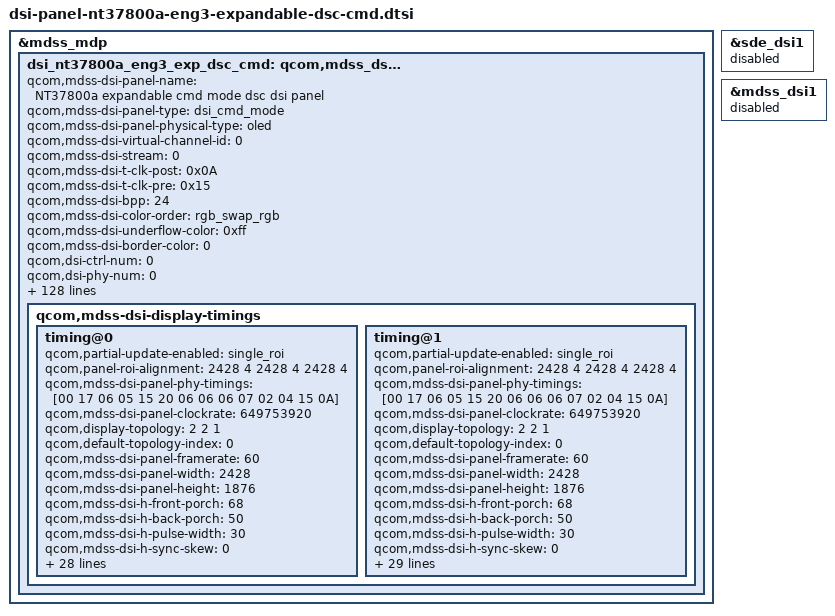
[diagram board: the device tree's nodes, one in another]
/* Copyright (c) 2014, Code Aurora Forum. All rights reserved.
 *
 * This program is free software; you can redistribute it and/or modify
 * it under the terms of the GNU General Public License version 2 and
 * only version 2 as published by the Free Software Foundation.
 *
 * This program is distributed in the hope that it will be useful,
 * but WITHOUT ANY WARRANTY; without even the implied warranty of
 * MERCHANTABILITY or FITNESS FOR A PARTICULAR PURPOSE.  See the
 * GNU General Public License for more details.
 */

/*
 * ===== 2nd working sample information =====
 *   [ DAh : 0x02, DBh : 0x01, DCh : 0x01 ]
 *  A. IRC(VDC) : not supported
 *  B. CM : not supported
 *  C. Demura : not supported
 *  D. PPA : supported
 *  E. AoD Band : not supported
 */
&mdss_mdp {
    dsi_nt37800a_eng3_exp_dsc_cmd: qcom,mdss_dsi_nt37800a_eng3_exp_dsc_cmd {
    qcom,mdss-dsi-panel-name = "NT37800a expandable cmd mode dsc dsi panel";
		qcom,mdss-dsi-panel-type = "dsi_cmd_mode";
		qcom,mdss-dsi-panel-physical-type = "oled";
		qcom,mdss-dsi-virtual-channel-id = <0>;
		qcom,mdss-dsi-stream = <0>;
		qcom,mdss-dsi-t-clk-post = <0x0A>;
		qcom,mdss-dsi-t-clk-pre = <0x15>;
		qcom,mdss-dsi-bpp = <24>;
		qcom,mdss-dsi-color-order = "rgb_swap_rgb";
		qcom,mdss-dsi-underflow-color = <0xff>;
		qcom,mdss-dsi-border-color = <0>;
		qcom,dsi-ctrl-num = <0>;
		qcom,dsi-phy-num = <0>;
		qcom,dsi-select-clocks = "mux_byte_clk0", "mux_pixel_clk0";
		qcom,mdss-dsi-traffic-mode = "burst_mode";
		qcom,mdss-dsi-lane-map = "lane_map_0123";
		qcom,mdss-dsi-bllp-eof-power-mode;
		qcom,mdss-dsi-bllp-power-mode;
		qcom,mdss-dsi-lane-0-state;
		qcom,mdss-dsi-lane-1-state;
		qcom,mdss-dsi-lane-2-state;
		qcom,mdss-dsi-lane-3-state;
		qcom,mdss-dsi-reset-sequence = <1 10>, <0 2>, <1 10>;
		qcom,mdss-dsi-dma-trigger = "trigger_sw";
		qcom,mdss-dsi-mdp-trigger = "none";
		qcom,mdss-dsi-te-pin-select = <1>;
		qcom,mdss-dsi-wr-mem-start = <0x2c>;
		qcom,mdss-dsi-wr-mem-continue = <0x3c>;
		qcom,mdss-dsi-te-dcs-command = <1>;
		//qcom,mdss-dsi-te-check-enable;
		//qcom,mdss-dsi-te-using-te-pin;
		qcom,mdss-dsi-lp11-init;
		qcom,mdss-dsi-tx-eot-append;
		qcom,ulps-enabled;

		/***************************** HDR *******************************/
		qcom,mdss-dsi-panel-hdr-enabled;
		qcom,mdss-dsi-panel-hdr-color-primaries = <14500 15500 32000
			17000 15500 30000 8000 3000>;
		qcom,mdss-dsi-panel-peak-brightness = <4200000>;
		qcom,mdss-dsi-panel-blackness-level = <3230>;

		qcom,mdss-pan-physical-width-dimension = <156>;
		qcom,mdss-pan-physical-height-dimension = <121>;

		/***************** Display Control ***********************/
		lge,mdss-dsi-reset-keep-high-after-off-cmd = <180>;

		lge,mdss-dsi-disp-ctrl-command-1 = [
			15 01 00 00 00 00 02 53 20
		];
		lge,mdss-dsi-disp-ctrl-command-1-state = "dsi_lp_mode";
		lge,mdss-dsi-disp-ctrl-command-2 = [
			15 01 00 00 00 00 02 55 00
			39 00 00 00 00 00 06 F0 55 AA 52 08 00
			15 00 00 00 00 00 02 6F 03
			39 00 00 00 00 00 02 D3 00
			39 01 00 00 00 00 06 F0 55 AA 52 00 00
		];
		lge,mdss-dsi-disp-ctrl-command-2-state = "dsi_lp_mode";

		/***************** Color Manager ***********************/
		lge,use-expandscreen-control;
		lge,use-color-manager;
		lge,color-manager-default-status = <1>;
		lge,mdss-dsi-color-manager-mode-table = <0 1>, <1 1>, <2 1>, <3 1>;

		lge,mdss-dsi-saturation-command = [
		39 00 00 00 00 00 06 F0 55 AA 52 08 00
		39 00 00 00 00 00 2E D1 38 36 37 37 36 36 36 39 33 29 2D 29 26 31 33 35 35 36 36 36 36 34 35 35 01 01 01 01 01 01 01 01 01 01 01 01 01 06 0C 03 09 0F 68 88 00
		39 01 00 00 00 00 06 F0 55 AA 52 00 00
		];
		lge,mdss-dsi-saturation-command-state = "dsi_hs_mode";

		lge,mdss-dsi-hue-command = [
		39 00 00 00 00 00 06 F0 55 AA 52 08 00
		39 00 00 00 00 00 34 D2 77 0C 40 96 83 93 80 7E 63 58 40 40 40 68 7E 78 94 94 94 8C 7A 7A 7A 7A 7D 86 8A 80 80 80 80 80 80 80 80 80 80 80 80 80 80 80 80 80 80 80 80 80 80 80 80
		39 01 00 00 00 00 06 F0 55 AA 52 00 00
		];
		lge,mdss-dsi-hue-command-state = "dsi_hs_mode";

		lge,mdss-dsi-sharpness-command = [
		39 00 00 00 00 00 06 F0 55 AA 52 08 00
		39 00 00 00 00 00 07 D3 02 00 00 01 10 00
		39 01 00 00 00 00 06 F0 55 AA 52 00 00
		];
		lge,mdss-dsi-sharpness-command-state = "dsi_hs_mode";

		lge,mdss-dsi-cm-natural = [
		39 00 00 00 00 00 06 F0 55 AA 52 08 00
		15 00 00 00 00 00 02 6F 00
		39 00 00 00 00 00 13 CE 00 40 40 40 40 3D 3D 3D 3D 40 40 40 40 40 40 40 40 40
		15 00 00 00 00 00 02 6F 13
		39 00 00 00 00 00 12 CE 45 45 45 45 45 45 45 45 45 45 45 45 45 45 45 45 40
		15 00 00 00 00 00 02 6F 24
		39 00 00 00 00 00 12 CE 42 42 42 42 42 42 42 42 42 42 42 42 42 42 42 40 40
		15 00 00 00 00 00 02 6F 35
		39 00 00 00 00 00 12 CE 40 40 40 40 40 40 40 40 40 40 40 40 40 40 40 40 40
		39 00 00 00 00 00 2E D1 38 36 37 37 36 36 36 39 33 29 2D 29 26 31 33 35 35 36 36 36 36 34 35 35 01 01 01 01 01 01 01 01 01 01 01 01 01 06 0C 03 09 0F 68 88 00
		39 00 00 00 00 00 34 D2 77 0C 40 96 83 93 80 7E 63 58 40 40 40 68 7E 78 94 94 94 8C 7A 7A 7A 7A 7D 86 8A 80 80 80 80 80 80 80 80 80 80 80 80 80 80 80 80 80 80 80 80 80 80 80 80
		39 01 00 00 00 00 06 F0 55 AA 52 00 00
		];
		lge,mdss-dsi-cm-natural-state = "dsi_hs_mode";

		lge,mdss-dsi-cm-vivid = [
		39 00 00 00 00 00 06 F0 55 AA 52 08 00
		15 00 00 00 00 00 02 6F 00
		39 00 00 00 00 00 13 CE 00 40 40 40 40 40 40 40 40 40 40 40 40 40 40 40 40 40
		15 00 00 00 00 00 02 6F 13
		39 00 00 00 00 00 12 CE 40 40 40 40 40 40 40 40 40 40 40 40 40 40 40 40 40
		15 00 00 00 00 00 02 6F 24
		39 00 00 00 00 00 12 CE 40 40 40 40 40 40 40 40 40 40 40 40 40 40 40 40 40
		15 00 00 00 00 00 02 6F 35
		39 00 00 00 00 00 12 CE 40 40 40 40 40 40 40 40 40 40 40 40 40 40 40 40 40
		39 00 00 00 00 00 2E D1 50 35 35 35 50 50 50 50 50 50 50 50 50 50 50 50 50 50 50 50 50 50 50 50 01 01 01 01 01 01 01 01 01 01 01 01 00 06 0C 03 09 0F 68 88 00
		39 00 00 00 00 00 34 D2 77 0C 40 80 80 95 80 80 80 80 80 80 80 80 80 80 80 80 80 80 80 80 80 80 80 80 80 80 80 80 80 80 80 80 80 80 80 80 80 80 80 80 80 80 80 80 80 80 80 80 80
		39 01 00 00 00 00 06 F0 55 AA 52 00 00
		];
		lge,mdss-dsi-cm-vivid-state = "dsi_hs_mode";

		lge,mdss-dsi-cm-cinema = [
		39 00 00 00 00 00 06 F0 55 AA 52 08 00
		15 00 00 00 00 00 02 6F 00
		39 00 00 00 00 00 13 CE 00 40 40 44 44 44 44 44 44 44 44 44 44 44 44 44 44 40
		15 00 00 00 00 00 02 6F 13
		39 00 00 00 00 00 12 CE 40 40 40 40 40 40 40 40 40 40 40 40 40 40 40 40 40
		15 00 00 00 00 00 02 6F 24
		39 00 00 00 00 00 12 CE 43 43 43 43 43 43 43 43 43 43 43 48 48 48 48 48 50
		15 00 00 00 00 00 02 6F 35
		39 00 00 00 00 00 12 CE 44 44 44 44 44 44 44 44 44 44 44 44 44 44 44 44 45
		39 00 00 00 00 00 2E D1 35 35 35 35 35 35 37 37 38 35 30 2C 2C 2C 30 32 35 35 35 35 35 34 33 35 44 14 11 11 11 11 11 15 11 11 21 44 00 06 0C 03 09 0F 68 88 00
		39 00 00 00 00 00 34 D2 77 0C 40 80 80 8D 85 80 80 70 60 50 60 7A 80 80 80 8A 8A 8A 80 7B 7B 78 76 74 80 80 80 80 80 80 80 80 80 80 80 80 80 80 80 80 80 80 80 80 80 80 80 80 80
		39 01 00 00 00 00 06 F0 55 AA 52 00 00
		];
		lge,mdss-dsi-cm-cinema-state = "dsi_hs_mode";

		/************************ Brightness ******************************/
		/* Brightness Map List */
		lge,blmap = <
			0
			3 3 3 3 6 6 6 6 6 6 6 7 7 8 8 9 10 11 13 14
			16 17 19 21 23 26 28 31 34 36 39 42 45 48 51 54 57 60 64 67
			70 73 76 80 83 86 89 92 96 99 103 107 111 116 120 125 129 133 138 142
			148 152 157 161 166 170 175 179 184 189 193 198 203 207 212 216 221 226 230 235
			239 244 248 253 257 261 266 270 275 280 284 289 293 297 302 306 311 316 321 326
			331 336 341 346 351 355 360 365 369 374 380 384 389 393 398 402 407 411 416 420
			426 430 436 441 446 452 456 461 466 472 477 482 486 491 496 501 506 511 516 521
			525 530 535 540 544 549 554 559 564 569 573 578 583 588 593 598 602 607 612 617
			622 627 631 636 641 645 650 654 659 664 669 674 678 683 687 691 696 700 704 708
			713 717 721 725 730 735 738 743 748 751 756 760 764 769 773 777 781 786 790 793
			797 802 806 810 814 819 822 827 831 835 839 843 847 852 856 861 865 869 874 878
			882 887 891 896 900 904 908 913 917 922 926 930 934 939 943 947 952 956 961 965
			969 974 978 982 986 991 995 999 1003 1008 1012 1016 1021 1025 1028 1028 1028 1028 1028 1028
			1029 1029 1029 1029 1029 1029 1029 1029 1029 1029 1029 1030 1030 1030 1030 1030 1031 1031 1031 1031
			1032 1032 1032 1033 1033 1033 1034 1034 1035 1035 1036 1036 1036 1037 1037 1038 1038 1038 1039 1039
			1040 1040 1041 1042 1042 1043 1043 1044 1045 1045 1046 1047 1047 1048 1049 1050 1050 1051 1052 1053
			1053 1054 1055 1072 1075 1089 1106 1122 1138 1153 1166 1172 1201 1216 1232 1248 1254 1278 1297 1306
			1323 1345 1361 1377 1408 1424 1440 1460 1477 1494 1513 1541 1557 1576 1605 1622 1650 1669 1687 1716
			1731 1751 1782 1804 1830
		>;

		lge,blmap-hl = <
			0
			36 36 36 36 36 36 36 36 36 36 36 36 37 37 38 39 40 42 43 45
			47 50 52 55 58 61 64 67 70 73 77 81 84 88 91 96 99 104 109 115
			119 125 130 136 141 148 153 159 164 170 176 182 188 194 200 206 212 218 224 229
			236 241 248 253 259 265 271 277 283 289 294 300 306 313 319 326 332 339 346 352
			358 365 371 378 384 390 396 403 409 415 421 428 435 442 450 456 463 470 477 484
			491 498 505 512 518 525 532 538 545 551 558 564 571 578 585 591 598 604 611 618
			625 631 638 644 651 657 664 670 676 682 689 695 700 706 712 718 724 730 736 742
			748 754 759 766 771 777 783 788 794 800 806 812 817 823 829 834 839 846 852 858
			864 870 876 882 887 894 900 905 911 918 924 930 935 941 947 953 959 965 971 977
			983 989 994 1000 1006 1012 1018 1024 1029 1035 1041 1048 1053 1122 1218 1314 1413 1510 1611 1707
			1807 1903 2002 2101 2188 2289 2378 2479 2578 2677 2775 2870 2971 3070 3167 3278 3371 3472 3557 3667
			3761 3876 3956 4047 4095 4095 4095 4095 4095 4095 4095 4095 4095 4095 4095 4095 4095 4095 4095 4095
			4095 4095 4095 4095 4095 4095 4095 4095 4095 4095 4095 4095 4095 4095 4095 4095 4095 4095 4095 4095
			4095 4095 4095 4095 4095 4095 4095 4095 4095 4095 4095 4095 4095 4095 4095 4095 4095 4095 4095 4095
			4095 4095 4095 4095 4095 4095 4095 4095 4095 4095 4095 4095 4095 4095 4095 4095 4095 4095 4095 4095
			4095 4095 4095 4095 4095 4095 4095 4095 4095 4095 4095 4095 4095 4095 4095 4095 4095 4095 4095 4095
			4095 4095 4095 4095 4095 4095 4095 4095 4095 4095 4095 4095 4095 4095 4095 4095 4095 4095 4095 4095
			4095 4095 4095 4095 4095 4095 4095 4095 4095 4095 4095 4095 4095 4095 4095 4095 4095 4095 4095 4095
			4095 4095 4095 4095 4095
		>;

		lge,blmap-ex = <
			0
			519 572 608 634 655 673 785 897 1004 1043 1097 1131 1184 1221 1259 1295 1331 1367 1403 1434
			1469 1504 1530 1562 1596 1620 1650 1674 1701 1726 1756 1775 1803 1829 1846 1878 1966 2042 2131 2204
			2277 2344 2403 2472 2525 2581 2634 2685 2740 2779 2830 2873 2918 2961 3009 3046 3083 3124 3159 3199
			3230 3272 3308 3335 3368 3403 3437 3471 3496 3526 3560 3590 3618 3647 3671 3720 3760 3798 3835 3871
			3907 3945 3978 3982 3984 3987 3989 3992 3995 3997 4000 4003 4005 4007 4009 4012 4014 4014 4015 4016
			4017 4018 4019 4020 4021 4022 4023 4024 4025 4026 4026 4027 4028 4029 4030 4032 4035 4037 4040 4042
			4045 4048 4051 4053 4055 4058 4060 4062 4064 4067 4069 4071 4073 4076 4076 4076 4076 4076 4076 4076
			4077 4078 4079 4081 4082 4083 4084 4085 4086 4087 4089 4090 4091 4092 4093 4094 4095 4095 4095 4095
			4095 4095 4095 4095 4095 4095 4095 4095 4095 4095 4095 4095 4095 4095 4095 4095 4095 4095 4095 4095
			4095 4095 4095 4095 4095 4095 4095 4095 4095 4095 4095 4095 4095 4095 4095 4095 4095 4095 4095 4095
			4095 4095 4095 4095 4095 4095 4095 4095 4095 4095 4095 4095 4095 4095 4095 4095 4095 4095 4095 4095
			4095 4095 4095 4095 4095 4095 4095 4095 4095 4095 4095 4095 4095 4095 4095 4095 4095 4095 4095 4095
			4095 4095 4095 4095 4095 4095 4095 4095 4095 4095 4095 4095 4095 4095 4095
		>;

		lge,blmap-hdr = <
			0
			6 6 6 6 6 6 6 6 6 6 6 7 7 8 8 9 10 12 13 15
			17 19 21 23 26 28 32 34 37 40 43 46 50 53 57 60 63 66 69 73
			77 80 84 87 90 94 97 101 106 110 115 120 124 129 134 139 143 149 154 158
			163 168 173 178 182 188 193 198 203 207 212 217 222 227 231 237 241 247 251 256
			260 265 270 275 280 285 290 294 299 303 308 314 319 325 330 335 340 345 351 356
			361 366 371 376 381 386 391 396 401 406 410 416 420 426 431 437 442 448 453 458
			464 469 475 480 485 490 495 501 506 512 517 522 527 532 537 542 548 552 557 563
			568 573 578 583 588 594 599 603 609 615 620 625 630 634 640 645 650 654 660 665
			670 675 679 685 689 694 698 703 707 712 716 721 725 730 735 739 744 749 753 758
			762 767 771 776 781 785 789 794 798 803 807 812 816 820 824 829 833 838 842 847
			851 856 861 866 870 875 879 884 889 893 898 902 907 912 917 921 926 931 935 940
			944 949 954 959 963 967 972 977 981 986 991 995 999 1004 1008 1013 1018 1023 1026 1031
			1036 1041 1045 1050 1055 1130 1202 1278 1353 1432 1510 1582 1669 1748 1830 1830 1830 1830 1830 1830
			1830 1830 1830 1830 1830 1830 1830 1830 1830 1830 1830 1830 1830 1830 1830 1830 1830 1830 1830 1830
			1830 1830 1830 1830 1830 1830 1830 1830 1830 1830 1830 1830 1830 1830 1830 1830 1830 1830 1830 1830
			1830 1830 1830 1830 1830 1830 1830 1830 1830 1830 1830 1830 1830 1830 1830 1830 1830 1830 1830 1830
			1830 1830 1830 1830 1830 1830 1830 1830 1830 1830 1830 1830 1830 1830 1830 1830 1830 1830 1830 1830
			1830 1830 1830 1830 1830 1830 1830 1830 1830 1830 1830 1830 1830 1830 1830 1830 1830 1830 1830 1830
			1830 1830 1830 1830 1830
		>;

//		lge,use-irc-ctrl; // ENG2 : NOT SUPPORTED
		lge,mdss-dsi-irc-command = [
			39 00 00 00 00 00 06 F0 55 AA 52 08 08
			15 00 00 00 00 00 02 B9 00
			39 01 00 00 00 00 06 F0 55 AA 52 00 00
		];
		lge,mdss-dsi-irc-command-state = "dsi_hs_mode";

		lge,use-hl-mode;
//		lge,use-bc-dim;
//		lge,bc-dimming-work;
		lge,mdss-dsi-bc-default-command = [
			39 00 00 00 00 00 06 F0 55 AA 52 08 00
			15 00 00 00 00 00 02 6F 02
			39 00 00 00 00 00 03 B2 01 01
			39 01 00 00 00 00 06 F0 55 AA 52 00 00
		];
		lge,mdss-dsi-bc-default-command-state = "dsi_hs_mode";

		lge,use-vr-lp-mode;
		lge,mdss-dsi-vr-lp-mode-on-command = [
			39 00 00 00 00 00 06 F0 55 AA 52 08 00
			15 00 00 00 00 00 02 6F 0F
			15 00 00 00 00 00 02 B2 00
			39 00 00 00 00 00 27 B4 06 86 06 86 05 0C 05 0C 03 1E 03 1E 01 68 01 68 05 32 05 32 05 32 05 32 05 32 05 32 05 32 05 32 05 32 05 32 05 32
			39 01 00 00 00 00 06 F0 55 AA 52 00 00
		];
		lge,mdss-dsi-vr-lp-mode-off-command = [
			39 00 00 00 00 00 06 F0 55 AA 52 08 00
			15 00 00 00 00 00 02 6F 0F
			15 00 00 00 00 00 02 B2 80
			39 00 00 00 00 00 27 B4 06 AE 06 AE 06 AE 06 2C 06 2C 04 B0 04 B0 02 8A 02 8A 00 6E 00 6E 00 6E 00 6E 04 B0 04 B0 02 8A 00 6E 00 6E 00 6E
			39 01 00 00 00 00 06 F0 55 AA 52 00 00
		];
		lge,mdss-dsi-vr-lp-command-state = "dsi_lp_mode";
		lge,blmap-vr = < 0 528 >;

		lge,mdss-dsi-expandable-area-command = [
			39 00 00 00 00 00 05 30 03 20 07 53
			39 01 00 00 00 00 05 32 00 00 02 AF
		];
		lge,mdss-dsi-expandable-area-command-state = "dsi_hs_mode";

		lge,mdss-dsi-expandable-area-enable-command = [
			15 01 00 00 00 00 02 63 00
			05 01 00 00 00 00 01 13
			15 01 00 00 00 00 02 84 03
		];
		lge,mdss-dsi-expandable-area-enable-command-state = "dsi_hs_mode";

		/*************************** AOD **********************************/
		lge,use-ambient;
		lge,aod-interface-data = "partial", "partial", "partial";
		lge,update-pps-in-lp-mode;
		lge,disp-br-ctrl-ext-supported;
		lge,ddic-dsi-br-ctrl-ext-command = [
			39 01 00 00 00 00 05 51 00 00 00 00
		];

		lge,mdss-dsi-nolp-command = [
			05 01 00 00 00 00 01 38
			15 01 00 00 00 00 02 65 00
			39 01 00 00 00 00 01 2C
			39 01 00 00 00 00 06 F0 55 AA 52 08 04
			15 01 00 00 00 00 02 D0 00
			39 01 00 00 00 00 06 F0 55 AA 52 00 00
		];
		lge,mdss-dsi-nolp-command-state = "dsi_lp_mode";
		lge,mdss-dsi-lp2-command = [
			15 01 00 00 00 00 02 84 00
			39 01 00 00 00 00 06 F0 55 AA 52 08 04
			15 01 00 00 00 00 02 D0 22
			39 01 00 00 00 00 06 F0 55 AA 52 00 00
			05 01 00 00 00 00 01 39
			15 01 00 00 00 00 02 65 01
			39 01 00 00 00 00 01 2C
			15 01 00 00 00 00 02 84 03
		];
		lge,mdss-dsi-lp2-command-state = "dsi_lp_mode";

		/************************* Factory *********************************/
		lge,use-line-detect;
		lge,detect-vert-line-restore-command = [
			39 00 00 00 00 00 06 F0 55 AA 52 08 01
			39 00 00 00 00 00 03 B0 00 00
			39 00 00 00 00 00 03 B3 03 03
			39 00 00 00 00 00 11 B7 14 14 14 14 14 14 14 14 14 14 14 14 14 14 14 14
			39 00 00 00 00 00 03 B1 00 00
			39 00 00 00 00 00 03 B4 03 03
			39 00 00 00 00 00 11 B8 41 41 41 41 41 41 41 41 41 41 41 41 41 41 41 41
			39 01 00 00 00 00 06 F0 55 AA 52 00 00
		];
		lge,detect-vert-line-restore-command-state = "dsi_hs_mode";
		lge,detect-black-vert-line-command = [
			39 00 00 00 00 00 06 F0 55 AA 52 08 01
			39 00 00 00 00 00 03 B0 00 00
			39 00 00 00 00 00 03 B3 03 03
			39 00 00 00 00 00 11 B7 32 32 32 32 32 32 32 32 32 32 32 32 32 32 32 32
			39 00 00 00 00 00 03 B1 00 00
			39 00 00 00 00 00 03 B4 03 03
			39 00 00 00 00 00 11 B8 2D 2D 2D 2D 2D 2D 2D 2D 2D 2D 2D 2D 2D 2D 2D 2D
			39 01 00 00 00 00 06 F0 55 AA 52 00 00
		];
		lge,detect-black-vert-line-command-state = "dsi_hs_mode";
		lge,detect-white-vert-line-command = [
			39 00 00 00 00 00 06 F0 55 AA 52 08 01
			39 00 00 00 00 00 03 B0 00 00
			39 00 00 00 00 00 03 B3 03 03
			39 00 00 00 00 00 11 B7 0A 0A 0A 0A 0A 0A 0A 0A 0A 0A 0A 0A 0A 0A 0A 0A
			39 00 00 00 00 00 03 B1 00 00
			39 00 00 00 00 00 03 B4 03 03
			39 00 00 00 00 00 11 B8 5F 5F 5F 5F 5F 5F 5F 5F 5F 5F 5F 5F 5F 5F 5F 5F
			39 01 00 00 00 00 06 F0 55 AA 52 00 00
		];
		lge,detect-white-vert-line-command-state = "dsi_hs_mode";

		lge,use-tc-perf;
		lge,mdss-dsi-tc-perf-on-command = [
			39 00 00 00 00 00 06 F0 55 AA 52 08 00
			15 00 00 00 00 00 02 6F 0F
			15 00 00 00 00 00 02 B2 00
			39 00 00 00 00 00 27 B4 06 86 06 86 05 0C 05 0C 03 1E 03 1E 01 68 01 68 00 26 00 26 00 26 00 26 00 26 00 26 00 26 00 26 00 26 00 26 00 08
			39 01 00 00 00 00 06 F0 55 AA 52 00 00
		];
		lge,mdss-dsi-tc-perf-on-command-state = "dsi_hs_mode";

		lge,mdss-dsi-tc-perf-off-command = [
			39 00 00 00 00 00 06 F0 55 AA 52 08 00
			15 00 00 00 00 00 02 6F 0F
			15 00 00 00 00 00 02 B2 80
			39 00 00 00 00 00 27 B4 06 AE 06 AE 06 AE 06 2C 06 2C 04 B0 04 B0 02 8A 02 8A 00 6E 00 6E 00 6E 00 6E 04 B0 04 B0 02 8A 00 6E 00 6E 00 6E
			39 01 00 00 00 00 06 F0 55 AA 52 00 00
		];
		lge,mdss-dsi-tc-perf-off-command-state = "dsi_hs_mode";

		qcom,mdss-dsi-display-timings {
			timing@0{
				qcom,partial-update-enabled = "single_roi";
				qcom,panel-roi-alignment = <2428 4 2428 4 2428 4>;
				qcom,mdss-dsi-panel-phy-timings = [00 17 06 05 15 20 06 06 06 07 02 04 15 0A]; /* To Do */
				qcom,mdss-dsi-panel-clockrate = <649753920>;
				qcom,display-topology = <2 2 1>;
				qcom,default-topology-index = <0>;
				qcom,mdss-dsi-panel-framerate = <60>;
				qcom,mdss-dsi-panel-width = <2428>;
				qcom,mdss-dsi-panel-height = <1876>;
				qcom,mdss-dsi-h-front-porch = <68>;
				qcom,mdss-dsi-h-back-porch = <50>;
				qcom,mdss-dsi-h-pulse-width = <30>;
				qcom,mdss-dsi-h-sync-skew = <0>;
				qcom,mdss-dsi-v-back-porch = <2>;
				qcom,mdss-dsi-v-front-porch = <4>;
				qcom,mdss-dsi-v-pulse-width = <2>;
				qcom,mdss-dsi-h-left-border = <0>;
				qcom,mdss-dsi-h-right-border = <0>;
				qcom,mdss-dsi-v-top-border = <0>;
				qcom,mdss-dsi-v-bottom-border = <0>;
				qcom,mdss-dsi-h-sync-pulse = <0>;
				//qcom,mdss-mdp-transfer-time-us = <15000>;

				qcom,mdss-dsi-on-command = [
					39 01 00 00 00 00 06 F0 55 AA 52 08 00
					15 01 00 00 00 00 02 B2 09
					39 01 00 00 00 00 19 CC 40 40 40 40 40 40 40 40 40 40 40 40 40 40 40 40 40 50 60 70 58 68 78 77
					15 01 00 00 00 00 02 6F 46
					39 01 00 00 00 00 12 CE 40 40 40 40 40 40 40 40 40 40 40 40 40 40 40 40 40
					15 01 00 00 00 00 02 6F 57
					39 01 00 00 00 00 12 CE 40 40 40 40 40 40 40 40 40 40 40 40 40 40 40 40 40
					15 01 00 00 00 00 02 6F 00
					39 01 00 00 00 00 03 D0 77 00
					15 01 00 00 00 00 02 6F 01
					39 01 00 00 00 00 03 D4 00 00
					39 01 00 00 00 00 19 DE 00 00 00 00 00 00 00 00 00 00 00 00 10 00 00 00 00 00 00 00 10 00 00 00
					39 01 00 00 00 00 06 F0 55 AA 52 08 01
					15 01 00 00 00 00 02 6F 02
					15 01 00 00 00 00 02 D2 00
					39 01 00 00 00 00 03 CD 05 82
					39 01 00 00 00 00 06 F0 55 AA 52 08 05
					15 01 00 00 00 00 02 6F 02
					15 01 00 00 00 00 02 B0 01
					39 01 00 00 00 00 06 F0 55 AA 52 08 07
					39 01 00 00 00 00 06 B0 84 40 78 70 00
					39 01 00 00 00 00 06 B1 0C 1C 00 1C 0C
					39 01 00 00 00 00 0A B2 30 30 30 30 30 30 30 30 30
					15 01 00 00 00 00 02 6F 36
					39 01 00 00 00 00 13 B2 32 32 32 32 32 32 32 32 32 77 77 77 77 77 77 77 77 77
					15 01 00 00 00 00 02 6F 09
					39 01 00 00 00 00 0A B2 90 90 90 90 90 90 90 90 90
					15 01 00 00 00 00 02 6F 48
					39 01 00 00 00 00 13 B2 33 33 33 33 33 33 33 33 33 79 79 79 79 79 79 79 79 79
					15 01 00 00 00 00 02 6F 12
					39 01 00 00 00 00 0A B2 FC FC FC FC FC FC FC FC FC
					15 01 00 00 00 00 02 6F 5A
					39 01 00 00 00 00 13 B2 03 03 03 03 03 03 03 03 03 9B 9B 9B 9B 9B 9B 9B 9B 9B
					15 01 00 00 00 00 02 6F 1B
					39 01 00 00 00 00 0A B2 90 90 90 90 90 90 90 90 90
					15 01 00 00 00 00 02 6F 6C
					39 01 00 00 00 00 13 B2 33 33 33 33 33 33 33 33 33 79 79 79 79 79 79 79 79 79
					15 01 00 00 00 00 02 6F 24
					39 01 00 00 00 00 0A B2 30 30 30 30 30 30 30 30 30
					15 01 00 00 00 00 02 6F 7E
					39 01 00 00 00 00 13 B2 32 32 32 32 32 32 32 32 32 77 77 77 77 77 77 77 77 77
					15 01 00 00 00 00 02 6F 2D
					39 01 00 00 00 00 0A B2 CC CC CC CC CC CC CC CC CC
					15 01 00 00 00 00 02 6F 90
					39 01 00 00 00 00 13 B2 03 03 03 03 03 03 03 03 03 3A 3A 3A 3A 3A 3A 3A 3A 3A
					15 01 00 00 00 00 02 B4 C0
					15 01 00 00 00 00 02 6F 01
					39 01 00 00 00 00 0D B4 80 80 80 80 60 80 60 80 80 80 80 80
					39 01 00 00 00 00 03 B7 00 00
					39 01 00 00 00 00 06 F0 55 AA 52 00 00
					39 01 00 00 00 00 05 FF AA 55 A5 80
					15 01 00 00 00 00 02 6F 50
					15 01 00 00 00 00 02 FB 00
					15 01 00 00 00 00 02 6F 61
					15 01 00 00 00 00 02 FB 80
					39 01 00 00 00 00 05 FF AA 55 A5 81
					39 01 00 00 00 00 05 FF AA 55 A5 00
					15 01 00 00 00 00 02 35 00
					39 01 00 00 00 00 05 3B 00 10 00 10
					39 01 00 00 00 00 05 51 00 00 0F FF
					15 01 00 00 00 00 02 53 20
					15 01 00 00 00 00 02 55 00
					15 01 00 00 00 00 02 03 01
					39 01 00 00 00 00 05 2A 00 00 09 7B
					39 01 00 00 00 00 05 2B 00 00 07 53
					39 01 00 00 00 00 05 30 02 AE 07 53
					39 01 00 00 00 00 05 31 00 00 09 7B
					39 01 00 00 00 00 05 32 00 00 02 AD
					39 01 00 00 00 00 05 33 00 00 09 7B
					15 01 00 00 00 00 02 63 03
					15 01 00 00 00 00 02 84 03
					15 01 00 00 00 00 02 90 81
					39 01 00 00 00 00 13 91 89 28 00 04 C2 00 03 60 00 72 00 10 20 00 0B 25 10 D0
					15 01 00 00 00 00 02 2C 00
					05 01 00 00 78 00 01 11
					05 01 00 00 00 00 01 29
					];

				qcom,mdss-dsi-post-panel-on-command = [
					//05 01 00 00 78 00 01 12
					//39 01 00 00 00 00 03 51 07 FF
				];

				qcom,mdss-dsi-off-command = [
					05 01 00 00 00 00 01 28
					05 01 00 00 20 00 01 10
				];

				qcom,compression-mode = "dsc";
				qcom,mdss-dsc-version = <0x11>;
				qcom,mdss-dsc-scr-version = <0x0>;
				qcom,mdss-dsc-slice-height = <4>;
				qcom,mdss-dsc-slice-width = <1214>;
				qcom,mdss-dsc-slice-per-pkt = <2>;
				qcom,mdss-dsc-bit-per-component = <8>;
				qcom,mdss-dsc-bit-per-pixel = <8>;
				qcom,lm-split = <1214 1214>;
				qcom,mdss-dsc-encoders = <2>;
				qcom,mdss-dsc-block-prediction-enable;

				qcom,mdss-dsi-on-command-state = "dsi_lp_mode";
				qcom,mdss-dsi-off-command-state = "dsi_lp_mode";

				qcom,mode-control-dsi-state = "dsi_lp_mode";
				qcom,mdss-dsi-pps-command-state = "dsi_hs_mode";
			};

			timing@1{
				qcom,partial-update-enabled = "single_roi";
				qcom,panel-roi-alignment = <2428 4 2428 4 2428 4>;
				qcom,mdss-dsi-panel-phy-timings = [00 17 06 05 15 20 06 06 06 07 02 04 15 0A]; /* To Do */
				qcom,mdss-dsi-panel-clockrate = <649753920>;
				qcom,display-topology = <2 2 1>;
				qcom,default-topology-index = <0>;
				qcom,mdss-dsi-panel-framerate = <60>;
				qcom,mdss-dsi-panel-width = <2428>;
				qcom,mdss-dsi-panel-height = <1876>;
				qcom,mdss-dsi-h-front-porch = <68>;
				qcom,mdss-dsi-h-back-porch = <50>;
				qcom,mdss-dsi-h-pulse-width = <30>;
				qcom,mdss-dsi-h-sync-skew = <0>;
				qcom,mdss-dsi-v-back-porch = <2>;
				qcom,mdss-dsi-v-front-porch = <4>;
				qcom,mdss-dsi-v-pulse-width = <2>;
				qcom,mdss-dsi-h-left-border = <0>;
				qcom,mdss-dsi-h-right-border = <0>;
				qcom,mdss-dsi-v-top-border = <0>;
				qcom,mdss-dsi-v-bottom-border = <0>;
				qcom,mdss-dsi-h-sync-pulse = <0>;
				//qcom,mdss-mdp-transfer-time-us = <15000>;
				lge,mdss-dsi-panel-framerate-div = <2>;

				qcom,mdss-dsi-on-command = [
					39 01 00 00 00 00 06 F0 55 AA 52 08 00
					15 01 00 00 00 00 02 B2 09
					39 01 00 00 00 00 19 CC 40 40 40 40 40 40 40 40 40 40 40 40 40 40 40 40 40 50 60 70 58 68 78 77
					15 01 00 00 00 00 02 6F 46
					39 01 00 00 00 00 12 CE 40 40 40 40 40 40 40 40 40 40 40 40 40 40 40 40 40
					15 01 00 00 00 00 02 6F 57
					39 01 00 00 00 00 12 CE 40 40 40 40 40 40 40 40 40 40 40 40 40 40 40 40 40
					15 01 00 00 00 00 02 6F 00
					39 01 00 00 00 00 03 D0 77 00
					15 01 00 00 00 00 02 6F 01
					39 01 00 00 00 00 03 D4 00 00
					39 01 00 00 00 00 19 DE 00 00 00 00 00 00 00 00 00 00 00 00 10 00 00 00 00 00 00 00 10 00 00 00
					39 01 00 00 00 00 06 F0 55 AA 52 08 01
					15 01 00 00 00 00 02 6F 02
					15 01 00 00 00 00 02 D2 00
					39 01 00 00 00 00 03 CD 05 82
					39 01 00 00 00 00 06 F0 55 AA 52 08 05
					15 01 00 00 00 00 02 6F 02
					15 01 00 00 00 00 02 B0 01
					39 01 00 00 00 00 06 F0 55 AA 52 08 07
					39 01 00 00 00 00 06 B0 84 40 78 70 00
					39 01 00 00 00 00 06 B1 0C 1C 00 1C 0C
					39 01 00 00 00 00 0A B2 30 30 30 30 30 30 30 30 30
					15 01 00 00 00 00 02 6F 36
					39 01 00 00 00 00 13 B2 32 32 32 32 32 32 32 32 32 77 77 77 77 77 77 77 77 77
					15 01 00 00 00 00 02 6F 09
					39 01 00 00 00 00 0A B2 90 90 90 90 90 90 90 90 90
					15 01 00 00 00 00 02 6F 48
					39 01 00 00 00 00 13 B2 33 33 33 33 33 33 33 33 33 79 79 79 79 79 79 79 79 79
					15 01 00 00 00 00 02 6F 12
					39 01 00 00 00 00 0A B2 FC FC FC FC FC FC FC FC FC
					15 01 00 00 00 00 02 6F 5A
					39 01 00 00 00 00 13 B2 03 03 03 03 03 03 03 03 03 9B 9B 9B 9B 9B 9B 9B 9B 9B
					15 01 00 00 00 00 02 6F 1B
					39 01 00 00 00 00 0A B2 90 90 90 90 90 90 90 90 90
					15 01 00 00 00 00 02 6F 6C
					39 01 00 00 00 00 13 B2 33 33 33 33 33 33 33 33 33 79 79 79 79 79 79 79 79 79
					15 01 00 00 00 00 02 6F 24
					39 01 00 00 00 00 0A B2 30 30 30 30 30 30 30 30 30
					15 01 00 00 00 00 02 6F 7E
					39 01 00 00 00 00 13 B2 32 32 32 32 32 32 32 32 32 77 77 77 77 77 77 77 77 77
					15 01 00 00 00 00 02 6F 2D
					39 01 00 00 00 00 0A B2 CC CC CC CC CC CC CC CC CC
					15 01 00 00 00 00 02 6F 90
					39 01 00 00 00 00 13 B2 03 03 03 03 03 03 03 03 03 3A 3A 3A 3A 3A 3A 3A 3A 3A
					15 01 00 00 00 00 02 B4 C0
					15 01 00 00 00 00 02 6F 01
					39 01 00 00 00 00 0D B4 80 80 80 80 60 80 60 80 80 80 80 80
					39 01 00 00 00 00 03 B7 00 00
					39 01 00 00 00 00 06 F0 55 AA 52 00 00
					39 01 00 00 00 00 05 FF AA 55 A5 80
					15 01 00 00 00 00 02 6F 50
					15 01 00 00 00 00 02 FB 00
					15 01 00 00 00 00 02 6F 61
					15 01 00 00 00 00 02 FB 80
					39 01 00 00 00 00 05 FF AA 55 A5 81
					39 01 00 00 00 00 05 FF AA 55 A5 00
					15 01 00 00 00 00 02 35 00
					39 01 00 00 00 00 05 3B 00 10 00 10
					39 01 00 00 00 00 05 51 00 00 0F FF
					15 01 00 00 00 00 02 53 20
					15 01 00 00 00 00 02 55 00
					15 01 00 00 00 00 02 03 01
					39 01 00 00 00 00 05 2A 00 00 09 7B
					39 01 00 00 00 00 05 2B 00 00 07 53
					39 01 00 00 00 00 05 30 02 AE 07 53
					39 01 00 00 00 00 05 31 00 00 09 7B
					39 01 00 00 00 00 05 32 00 00 02 AD
					39 01 00 00 00 00 05 33 00 00 09 7B
					15 01 00 00 00 00 02 63 03
					15 01 00 00 00 00 02 84 03
					15 01 00 00 00 00 02 90 81
					39 01 00 00 00 00 13 91 89 28 00 04 C2 00 03 60 00 72 00 10 20 00 0B 25 10 D0
					15 01 00 00 00 00 02 2C 00
					05 01 00 00 78 00 01 11
					05 01 00 00 00 00 01 29
					];

				qcom,mdss-dsi-post-panel-on-command = [
					//05 01 00 00 78 00 01 12
					//39 01 00 00 00 00 03 51 07 FF
				];

				qcom,mdss-dsi-off-command = [
					05 01 00 00 00 00 01 28
					05 01 00 00 20 00 01 10
				];

				qcom,compression-mode = "dsc";
				qcom,mdss-dsc-version = <0x11>;
				qcom,mdss-dsc-scr-version = <0x0>;
				qcom,mdss-dsc-slice-height = <4>;
				qcom,mdss-dsc-slice-width = <1214>;
				qcom,mdss-dsc-slice-per-pkt = <2>;
				qcom,mdss-dsc-bit-per-component = <8>;
				qcom,mdss-dsc-bit-per-pixel = <8>;
				qcom,lm-split = <1214 1214>;
				qcom,mdss-dsc-encoders = <2>;
				qcom,mdss-dsc-block-prediction-enable;

				qcom,mdss-dsi-on-command-state = "dsi_lp_mode";
				qcom,mdss-dsi-off-command-state = "dsi_lp_mode";

				qcom,mode-control-dsi-state = "dsi_lp_mode";
				qcom,mdss-dsi-pps-command-state = "dsi_hs_mode";
			};

		};
	};
};

&sde_dsi1 {
	status = "disabled";
};

&mdss_dsi1 {
	status = "disabled";
};
